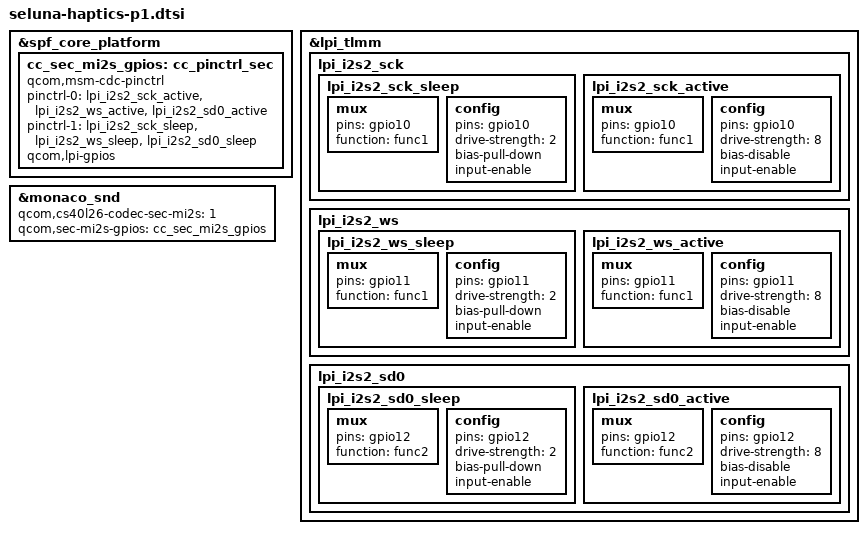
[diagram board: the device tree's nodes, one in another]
// SPDX-License-Identifier: GPL-2.0

#include <dt-bindings/interrupt-controller/irq.h>
#include "seluna-haptics.dtsi"

&spf_core_platform {
	cc_sec_mi2s_gpios: cc_pinctrl_sec {
		compatible = "qcom,msm-cdc-pinctrl";
		pinctrl-names = "aud_active", "aud_sleep";
		pinctrl-0 = <&lpi_i2s2_sck_active &lpi_i2s2_ws_active
				&lpi_i2s2_sd0_active>;

		pinctrl-1 = <&lpi_i2s2_sck_sleep &lpi_i2s2_ws_sleep
				&lpi_i2s2_sd0_sleep>;
		qcom,lpi-gpios;
		#gpio-cells = <0>;
	};
};

&lpi_tlmm {
	lpi_i2s2_sck {
		lpi_i2s2_sck_sleep: lpi_i2s2_sck_sleep {
			mux {
				pins = "gpio10";
				function = "func1";
			};

			config {
				pins = "gpio10";
				drive-strength = <2>;   /* 2 mA */
				bias-pull-down;         /* PULL DOWN */
				input-enable;
			};
		};

		lpi_i2s2_sck_active: lpi_i2s2_sck_active {
			mux {
				pins = "gpio10";
				function = "func1";
			};

			config {
				pins = "gpio10";
				drive-strength = <8>;   /* 8 mA */
				bias-disable;           /* NO PULL */
				input-enable;
			};
		};
	};

	lpi_i2s2_ws {
		lpi_i2s2_ws_sleep: lpi_i2s2_ws_sleep {
			mux {
				pins = "gpio11";
				function = "func1";
			};

			config {
				pins = "gpio11";
				drive-strength = <2>;   /* 2 mA */
				bias-pull-down;         /* PULL DOWN */
				input-enable;
			};
		};

		lpi_i2s2_ws_active: lpi_i2s2_ws_active {
			mux {
				pins = "gpio11";
				function = "func1";
			};

			config {
				pins = "gpio11";
				drive-strength = <8>;   /* 8 mA */
				bias-disable;           /* NO PULL */
				input-enable;
			};
		};
	};

	lpi_i2s2_sd0 {
		lpi_i2s2_sd0_sleep: lpi_i2s2_sd0_sleep {
			mux {
				pins = "gpio12";
				function = "func2";
			};

			config {
				pins = "gpio12";
				drive-strength = <2>;   /* 2 mA */
				bias-pull-down;         /* PULL DOWN */
				input-enable;
			};
		};

		lpi_i2s2_sd0_active: lpi_i2s2_sd0_active {
			mux {
				pins = "gpio12";
				function = "func2";
			};

			config {
				pins = "gpio12";
				drive-strength = <8>;   /* 8 mA */
				bias-disable;           /* NO PULL */
				input-enable;
			};
		};
	};
};

&monaco_snd {
	/delete-property/ qcom,cs40l26-codec-pri-mi2s;
	/delete-property/ qcom,pri-mi2s-gpios;
	qcom,cs40l26-codec-sec-mi2s = <1>;
	qcom,sec-mi2s-gpios = <&cc_sec_mi2s_gpios>;
};
